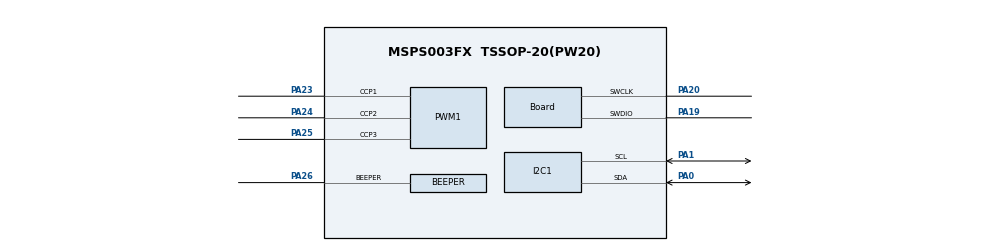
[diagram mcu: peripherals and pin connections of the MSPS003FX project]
/**
 * @cliArgs --device "MSPS003FX" --part "Default" --package "TSSOP-20(PW20)" --product "mspm0_sdk@2.03.00.07"
 * @versions {"tool":"1.22.0+3893"}
 */

/**
 * Import the modules used in this configuration.
 */
const ADC12         = scripting.addModule("/ti/driverlib/ADC12", {}, false);
const ADC121        = ADC12.addInstance();
const BEEPER        = scripting.addModule("/ti/driverlib/BEEPER");
const CRC           = scripting.addModule("/ti/driverlib/CRC");
const I2C           = scripting.addModule("/ti/driverlib/I2C", {}, false);
const I2C1          = I2C.addInstance();
const PWM           = scripting.addModule("/ti/driverlib/PWM", {}, false);
const PWM1          = PWM.addInstance();
const SYSCTL        = scripting.addModule("/ti/driverlib/SYSCTL");
const TIMER         = scripting.addModule("/ti/driverlib/TIMER", {}, false);
const TIMER1        = TIMER.addInstance();
const ProjectConfig = scripting.addModule("/ti/project_config/ProjectConfig");

/**
 * Write custom configuration values to the imported modules.
 */
ADC121.$name                      = "ADC12_0";
ADC121.sampClkDiv                 = "DL_ADC12_CLOCK_DIVIDE_8";
ADC121.powerDownMode              = "DL_ADC12_POWER_DOWN_MODE_MANUAL";
ADC121.sampleTime0                = "125 us";
ADC121.enabledInterrupts          = ["DL_ADC12_INTERRUPT_MEM0_RESULT_LOADED"];
ADC121.sampClkSrc                 = "DL_ADC12_CLOCK_ULPCLK";
ADC121.resolution                 = "DL_ADC12_SAMP_CONV_RES_12_BIT";
ADC121.peripheral.$assign         = "ADC0";
ADC121.peripheral.adcPin0.$assign = "PA27";
ADC121.adcPin0Config.$name        = "ti_driverlib_gpio_GPIOPinGeneric0";

BEEPER.beeperEnable                 = true;
BEEPER.beeperFreq                   = "8";
BEEPER.peripheral.$assign           = "SYSCTL";
BEEPER.peripheral.beeperPin.$assign = "PA26";

const Board                       = scripting.addModule("/ti/driverlib/Board", {}, false);
Board.peripheral.$assign          = "DEBUGSS";
Board.peripheral.swclkPin.$assign = "PA20";
Board.peripheral.swdioPin.$assign = "PA19";

CRC.seed = 0xFFFF;

I2C1.$name                     = "I2C_0";
I2C1.basicEnableController     = true;
I2C1.peripheral.sdaPin.$assign = "PA0";
I2C1.peripheral.sclPin.$assign = "PA1";
I2C1.sdaPinConfig.$name        = "ti_driverlib_gpio_GPIOPinGeneric4";
I2C1.sclPinConfig.$name        = "ti_driverlib_gpio_GPIOPinGeneric5";

PWM1.$name                      = "PWM_0";
PWM1.ccIndex                    = [1,2,3];
PWM1.timerStartTimer            = true;
PWM1.pwmMode                    = "EDGE_ALIGN_UP";
PWM1.peripheral.$assign         = "TIMG14";
PWM1.peripheral.ccp1Pin.$assign = "PA23";
PWM1.peripheral.ccp2Pin.$assign = "PA24";
PWM1.peripheral.ccp3Pin.$assign = "PA25";
PWM1.ccp1PinConfig.$name        = "ti_driverlib_gpio_GPIOPinGeneric2";
PWM1.PWM_CHANNEL_2.$name        = "ti_driverlib_pwm_PWMTimerCC1";
PWM1.PWM_CHANNEL_2.invert       = true;
PWM1.PWM_CHANNEL_3.$name        = "ti_driverlib_pwm_PWMTimerCC2";
PWM1.PWM_CHANNEL_3.invert       = true;
PWM1.ccp2PinConfig.$name        = "ti_driverlib_gpio_GPIOPinGeneric1";
PWM1.ccp3PinConfig.$name        = "ti_driverlib_gpio_GPIOPinGeneric3";
PWM1.PWM_CHANNEL_1.$name        = "ti_driverlib_pwm_PWMTimerCC0";
PWM1.PWM_CHANNEL_1.invert       = true;

SYSCTL.peripheral.$assign = "SYSCTL";

TIMER1.$name              = "TIMER_0";
TIMER1.profile            = "Basic_Periodic";
TIMER1.peripheral.$assign = "TIMA0";

ProjectConfig.migrationCondition = true;

/**
 * Pinmux solution for unlocked pins/peripherals. This ensures that minor changes to the automatic solver in a future
 * version of the tool will not impact the pinmux you originally saw.  These lines can be completely deleted in order to
 * re-solve from scratch.
 */
I2C1.peripheral.$suggestSolution = "I2C0";
